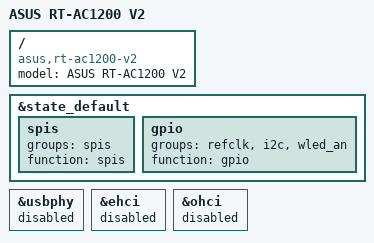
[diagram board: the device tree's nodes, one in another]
// SPDX-License-Identifier: GPL-2.0-or-later OR MIT

#include "mt7628an_asus_rt-ac1200.dtsi"

/ {
	compatible = "asus,rt-ac1200-v2", "mediatek,mt7628an-soc";
	model = "ASUS RT-AC1200 V2";
};

&state_default {
	spis {
		groups = "spis";
		function = "spis";
	};

	gpio {
		groups = "refclk", "i2c", "wled_an";
		function = "gpio";
	};
};

&usbphy {
	status = "disabled";
};

&ehci {
	status = "disabled";
};

&ohci {
	status = "disabled";
};
